# V32F20x_CM33 register map
File version: 1.0.3
CPU: CM33 r0p4, little endian, MPU, FPU, DSP, 3 interrupt priority bits, 8 SAU regions
Registers are 32-bit, read-write, reset 0x0 unless marked. A register's access mark holds for its fields unless they carry their own. Offsets are from the block's base; [hi:lo] are bit positions; 'fields as' and 'values as' point back to an identical list.

## PMU — PMU Peripheral Interface
Base 0x40100800
Same registers: SEC_PMU 0x50100800
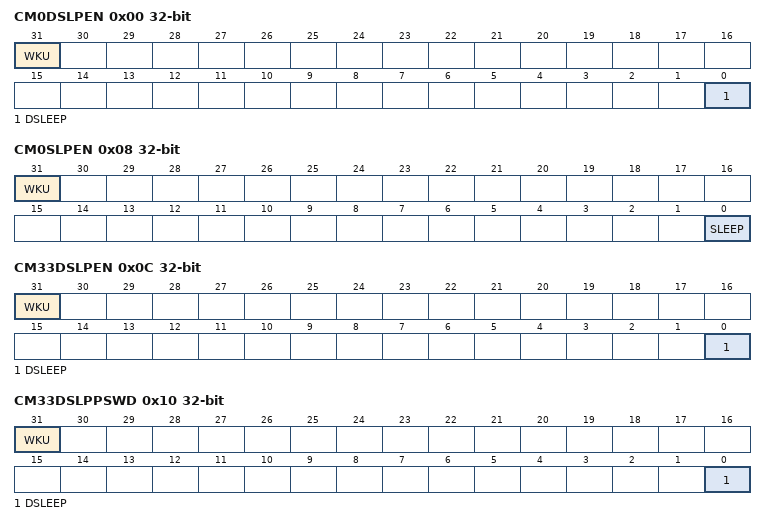
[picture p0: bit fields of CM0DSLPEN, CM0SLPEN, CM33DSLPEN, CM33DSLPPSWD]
0x00 CM0DSLPEN — CM0 deep sleep enable register
  [31] WKU — Current wake up signal this bit reflects the CM0 wake up status receive by PMU controller programmer must make sure this bit is 0 before entering deep sleep mode otherwise the system will wake up immediately because of non clear wake up event
  [0] DSLEEP — This bit indicates the CM0 deep sleep mode has been entry
0x04 CM0DSLPPSWD — CM0 deep sleep password register
  [0] UNLOCK — This bit indicates the CM0 deep sleep mode has unlocked and is ready to entry deep sleep mode
0x08 CM0SLPEN — CM0 sleep enable register
  [31] WKU — Current wake up signal this bit reflects the CM0 wake up status receive by PMU controller programmer must make sure this bit is 0 before entering sleep mode otherwise the system will wake up immediately because of non clear wake up event
  [0] SLEEP — This bit indicates the CM0 sleep mode has unlocked and is ready to entry sleep mode
0x0C CM33DSLPEN — CM33 deep sleep enable register
  [31] WKU — Current wake up signal this bit reflects the CM33 wake up status receive by PMU controller programmer must make sure this bit is 0 before entering deep sleep mode otherwise the system will wake up immediately because of non clear wake up event
  [0] DSLEEP — This bit indicates CM0 control the CM33 enter deep sleep mode
0x10 CM33DSLPPSWD — CM33 deep sleep password register
  fields as CM33DSLPEN
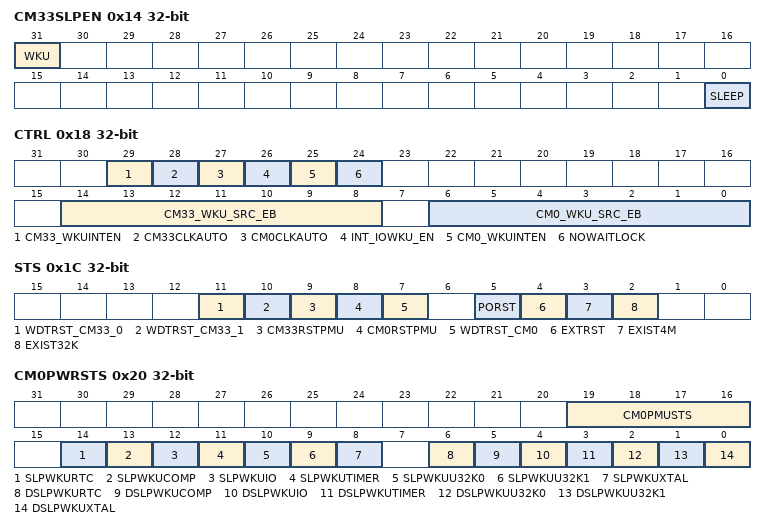
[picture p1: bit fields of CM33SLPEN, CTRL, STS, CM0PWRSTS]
0x14 CM33SLPEN — CM33 sleep enable register
  [31] WKU — Current wake up signal this bit reflects the CM33 wake up status receive by PMU controller programmer must make sure this bit is 0 before entering deep sleep mode otherwise the system will wake up immediately because of non clear wake up event
  [0] SLEEP — This bit indicates the CM33 sleep mode has unlocked and is ready to entry sleep mode
0x18 CTRL — PMU control register
  [29] CM33_WKUINTEN — CM33 Wake up interrupt enable.
  [28] CM33CLKAUTO — Whether to make the BGP1 RCH1 PLLL and PLLH power down when CM33 in deep sleep or sleep mode
  [27] CM0CLKAUTO — Whether to make the BGP1 RCH1 PLLL and PLLH power down when CM0 in deep sleep or sleep mode
  [26] INT_IOWKU_EN — Enable interrupt of the io wakeup source
  [25] CM0_WKUINTEN — CM0 Wake up interrupt enable.
  [24] NOWAITLOCK — Override the PLLH PLLL Lock from Analog module when this bit set
  [14:8] CM33_WKU_SRC_EB — CM33 wake up source enable:
  [6:0] CM0_WKU_SRC_EB — CM0 wake up source enable:
0x1C STS — PMU status register
  [11] WDTRST_CM33_0 — This bit indicated if the last interrupt is cause by watch dog timer
  [10] WDTRST_CM33_1 — This bit indicated if the last interrupt is cause by watch dog timer
  [9] CM33RSTPMU — This bit indicated if the last interrupt is cause by
  [8] CM0RSTPMU — This bit indicated if the last interrupt is cause by
  [7] WDTRST_CM0 — This bit indicated if the last interrupt is cause by watch dog timer
  [5] PORST — This bit indicated if the last interrupt is cause by internal power on reset signal
  [4] EXTRST — This bit indicated if the last interrupt is cause by external reset signal
  [3] EXIST4M — XOH exist status register
  [2] EXIST32K — 32K XTAL exist status register
0x20 CM0PWRSTS — CM0 power status register
  [19:16] CM0PMUSTS — CM0 PMU state machine code.
  [14] SLPWKURTC — This register is used to indicate if the previous wake up source from sleep mode is from RTC module
  [13] SLPWKUCOMP — This register is used to indicate if the previous wake up source from sleep mode is from Analog module be compare
  [12] SLPWKUIO — This register is used to indicate if the previous wakeup source from sleep mode is from IO wake up
  [11] SLPWKUTIMER — This register is used to indicate if the previous wakeup source from sleep mode is from timer
  [10] SLPWKUU32K0 — This register is used to indicate if the previous wakeup source from sleep mode is from UART32K 0 module
  [9] SLPWKUU32K1 — This register is used to indicate if the previous wake up source from deep sleep mode is from UART32K 1 module
  [8] SLPWKUXTAL — This register is used to indicate if the previous wake
  [6] DSLPWKURTC — This register is used to indicate if the previous wake up source from deep sleep mode is from RTC module
  [5] DSLPWKUCOMP — This register is used to indicate if the previous wake up source from deep sleep mode is from Analog module be compare
  [4] DSLPWKUIO — This register is used to indicate if the previous wake up source from deep sleep mode is from IO wakeup
  [3] DSLPWKUTIMER — This register is used to indicate if the previous wake up source from deep sleep mode is from timer
  [2] DSLPWKUU32K0 — This register is used to indicate if the previous wake up source from deep sleep mode is from UART32K 0 module
  [1] DSLPWKUU32K1 — This register is used to indicate if the previous wake up source from deep sleep mode is from UART32K 1 module
  [0] DSLPWKUXTAL — This register is used to indicate if the previous wake up source from CM0 deep sleep mode is from crystal absent detection module
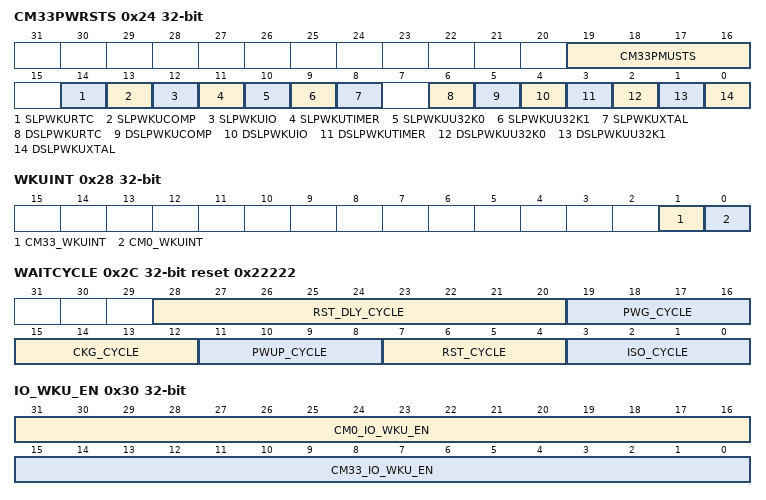
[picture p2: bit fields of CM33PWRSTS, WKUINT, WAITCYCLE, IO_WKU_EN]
0x24 CM33PWRSTS — CM33 power status register
  [19:16] CM33PMUSTS — CM33 PMU state machine code.
  [14] SLPWKURTC — This register is used to indicate if the previous wake up source from sleep mode is from RTC module
  [13] SLPWKUCOMP — This register is used to indicate if the previous wake up source from sleep mode is from Analog module be compare
  [12] SLPWKUIO — This register is used to indicate if the previous wake up source from sleep mode is from IO wake up
  [11] SLPWKUTIMER — This register is used to indicate if the previous wake up source from sleep mode is from timer
  [10] SLPWKUU32K0 — This register is used to indicate if the previous wake up source from sleep mode is from UART32K 0 module
  [9] SLPWKUU32K1 — This register is used to indicate if the previous wake up source from deep sleep mode is from UART32K 1 module
  [8] SLPWKUXTAL — This register is used to indicate if the previous wake up source from CM0 sleep mode is from crystal absent detection module
  [6] DSLPWKURTC — This register is used to indicate if the previous wake up source from deep sleep mode is from RTC module
  [5] DSLPWKUCOMP — This register is used to indicate if the previous wake up source from deep sleep mode is from Analog module be compare
  [4] DSLPWKUIO — This register is used to indicate if the previous wake up source from deep sleep mode is from IO wakeup
  [3] DSLPWKUTIMER — This register is used to indicate if the previous wake up source from deep sleep mode is from timer
  [2] DSLPWKUU32K0 — This register is used to indicate if the previous wake up source from deep sleep mode is from UART32K 0 module
  [1] DSLPWKUU32K1 — This register is used to indicate if the previous wake up source from deep sleep mode is from UART32K 1 module
  [0] DSLPWKUXTAL — This register is used to indicate if the previous wake up source from CM33 deep sleep mode is from crystal absent detection module
0x28 WKUINT — Wakeup int register
  [1] CM33_WKUINT — This bit represents the CM33 wake up source interrupt status
  [0] CM0_WKUINT — This bit represents the CM0 wake up source interrupt status
0x2C WAITCYCLE reset 0x22222 — PMU_WAITCYCLE
  [28:20] RST_DLY_CYCLE — Assert additional reset delay time to ensure CM0 flash wakeup timing 5us
  [19:16] PWG_CYCLE — Power gate cycle count this register control the power gate wait time when a wake up even is received
  [15:12] CKG_CYCLE — clkgate wait cycle count this register control the clkgate state wait time
  [11:8] PWUP_CYCLE — Power up cycle count this register control the power up wait time when a wake up even is received
  [7:4] RST_CYCLE — RST assert or de assert cycle count this register control the RST state wait time
  [3:0] ISO_CYCLE — ISO on or off cycle count this register control the isolation state wait time
0x30 IO_WKU_EN — IO_WKU_EN Abstract
  [31:16] CM0_IO_WKU_EN — IO wakeup CM0 enable, corresponding EXIO0 to XIO15
  [15:0] CM33_IO_WKU_EN — IO wakeup CM33 enable corresponding EXIO0 to EXIO15
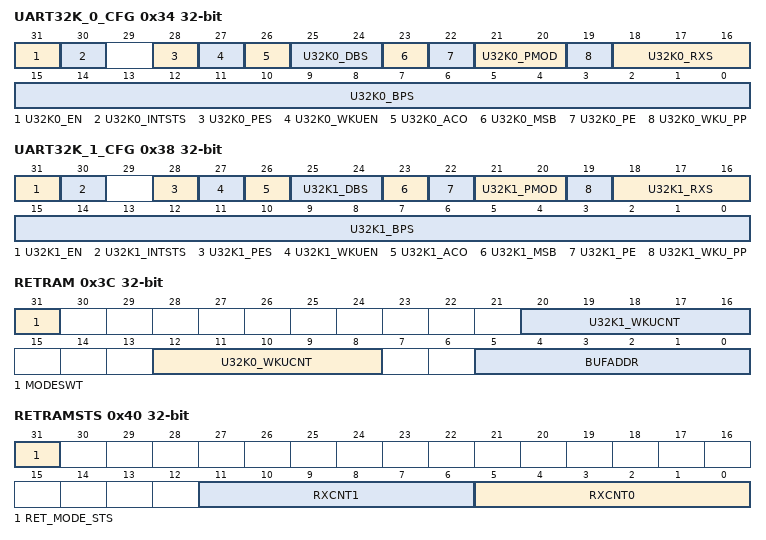
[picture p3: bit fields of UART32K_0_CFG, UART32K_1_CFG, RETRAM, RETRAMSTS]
0x34 UART32K_0_CFG — UART32K_0_CFG Abstract
  [31] U32K0_EN — UART 32K controller enable register
  [30] U32K0_INTSTS — Uart32K0 interrupt status.
  [28] U32K0_PES — This bit is set when the parity or stop bit is error
  [27] U32K0_WKUEN — Enable the UART32K0 wakeup to PMU CTRL
  [26] U32K0_ACO — Auto calibration off control register
  [25:24] U32K0_DBS — De-bounce control register
  [23] U32K0_MSB — UART receive order control register.
  [22] U32K0_PE — UART parity enable register.
  [21:20] U32K0_PMOD — Parity mode control register this register is valid only when MODE is set to 1
  [19] U32K0_WKU_PP — Only received a good data with parity check pass then the module will try to wake up system
  [18:16] U32K0_RXS — Receive data select
  [15:0] U32K0_BPS — Baud rate divider register this register must be set before enable UART 32K engine
0x38 UART32K_1_CFG — UART32K_1_CFG Abstract
  [31] U32K1_EN — UART 32K controller enable register
  [30] U32K1_INTSTS — Uart32K1 interrupt status.
  [28] U32K1_PES — This bit is set when the parity or stop bit is error
  [27] U32K1_WKUEN — Enable the UART32K1 wakeup to PMU CTRL
  [26] U32K1_ACO — Auto calibration off control register
  [25:24] U32K1_DBS — De-bounce control register
  [23] U32K1_MSB — UART receive order control register.
  [22] U32K1_PE — UART parity enable register.
  [21:20] U32K1_PMOD — Parity mode control register this register is valid only when MODE is set to 1
  [19] U32K1_WKU_PP — Only received a good data with parity check pass then the module will try to wake up system
  [18:16] U32K1_RXS — Receive data select
  [15:0] U32K1_BPS — Baud rate divider register this register must be set before enable UART 32K engine
0x3C RETRAM — Retention RAM configuration register.
  [31] MODESWT — Retention RAM mode switch.
  [20:16] U32K1_WKUCNT — Receive data counts to generate wakeup source.
  [12:8] U32K0_WKUCNT — Receive data counts to generate wakeup source.
  [5:0] BUFADDR — LPUART RX buffer base address configuration of uart32k0
0x40 RETRAMSTS — Retention RAM status register
  [31] RET_MODE_STS — Retention RAM mode status:
  [11:6] RXCNT1 — UART32K1 valid byte count in RX buffer, max is 32.
  [5:0] RXCNT0 — UART32K0 valid byte count in RX buffer, max is 32.
